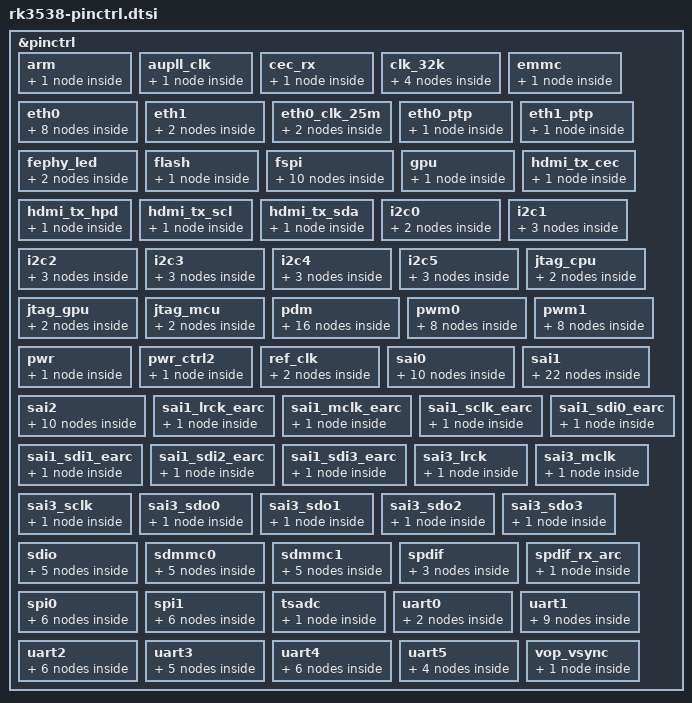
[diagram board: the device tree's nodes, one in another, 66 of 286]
// SPDX-License-Identifier: (GPL-2.0+ OR MIT)
/*
 * Copyright (c) 2025 Rockchip Electronics Co., Ltd.
 */

#include <dt-bindings/pinctrl/rockchip.h>
#include "rv1126b-pinconf.dtsi"

/*
 * This file is auto generated by pin2dts tool, please keep these code
 * by adding changes at end of this file.
 */
&pinctrl {
	arm {
		/omit-if-no-ref/
		arm_pins: arm-pins {
			rockchip,pins =
				/* arm_avs */
				<0 RK_PB5 3 &pcfg_pull_none>;
		};
	};

	aupll_clk {
		/omit-if-no-ref/
		aupll_clk_pins: aupll-clk-pins {
			rockchip,pins =
				/* aupll_clk_in */
				<0 RK_PA1 3 &pcfg_pull_none>;
		};
	};

	cec_rx {
		/omit-if-no-ref/
		cec_rx_pins: cec-rx-pins {
			rockchip,pins =
				/* cec_rx_testout */
				<0 RK_PD1 3 &pcfg_pull_none>;
		};
	};

	clk_32k {
		/omit-if-no-ref/
		clk_32km0_pins: clk-32km0-pins {
			rockchip,pins =
				/* clk_32k_out_m0 */
				<3 RK_PC2 3 &pcfg_pull_none>;
		};

		/omit-if-no-ref/
		clk_32km1_pins: clk-32km1-pins {
			rockchip,pins =
				/* clk_32k_out_m1 */
				<5 RK_PC2 6 &pcfg_pull_none>;
		};

		/omit-if-no-ref/
		clk_32km2_pins: clk-32km2-pins {
			rockchip,pins =
				/* clk_32k_out_m2 */
				<0 RK_PD4 1 &pcfg_pull_none>;
		};

		/omit-if-no-ref/
		clk_32k_in_pins: clk-32k-in-pins {
			rockchip,pins =
				/* clk_32k_in */
				<0 RK_PD4 3 &pcfg_pull_none>;
		};
	};

	emmc {
		/omit-if-no-ref/
		emmc_pins: emmc-pins {
			rockchip,pins =
				/* emmc_clk */
				<1 RK_PB1 1 &pcfg_pull_none>,
				/* emmc_cmd */
				<1 RK_PB0 1 &pcfg_pull_none>,
				/* emmc_d0 */
				<1 RK_PA0 1 &pcfg_pull_none>,
				/* emmc_d1 */
				<1 RK_PA1 1 &pcfg_pull_none>,
				/* emmc_d2 */
				<1 RK_PA2 1 &pcfg_pull_none>,
				/* emmc_d3 */
				<1 RK_PA3 1 &pcfg_pull_none>,
				/* emmc_d4 */
				<1 RK_PA4 1 &pcfg_pull_none>,
				/* emmc_d5 */
				<1 RK_PA5 1 &pcfg_pull_none>,
				/* emmc_d6 */
				<1 RK_PA6 1 &pcfg_pull_none>,
				/* emmc_d7 */
				<1 RK_PA7 1 &pcfg_pull_none>,
				/* emmc_rstn */
				<1 RK_PB3 1 &pcfg_pull_none>,
				/* emmc_strb */
				<1 RK_PB2 1 &pcfg_pull_none>;
		};
	};

	eth0 {
		/omit-if-no-ref/
		eth0_miim_pins: eth0-miim-pins {
			rockchip,pins =
				/* eth0_mdc */
				<5 RK_PB5 1 &pcfg_pull_none>,
				/* eth0_mdio */
				<5 RK_PB6 1 &pcfg_pull_none>;
		};

		/omit-if-no-ref/
		eth0_mclk_pins: eth0-mclk-pins {
			rockchip,pins =
				/* eth0_mclk */
				<5 RK_PB3 1 &pcfg_pull_none>;
		};

		/omit-if-no-ref/
		eth0_rx_bus2_pins: eth0-rx-bus2-pins {
			rockchip,pins =
				/* eth0_rxctl */
				<5 RK_PC1 1 &pcfg_pull_none>,
				/* eth0_rxd0 */
				<5 RK_PB2 1 &pcfg_pull_none>,
				/* eth0_rxd1 */
				<5 RK_PB1 1 &pcfg_pull_none>;
		};

		/omit-if-no-ref/
		eth0_tx_bus2_pins: eth0-tx-bus2-pins {
			rockchip,pins =
				/* eth0_txctl */
				<5 RK_PB7 1 &pcfg_pull_none>,
				/* eth0_txd0 */
				<5 RK_PB0 1 &pcfg_pull_none>,
				/* eth0_txd1 */
				<5 RK_PA7 1 &pcfg_pull_none>;
		};

		/omit-if-no-ref/
		eth0_rgmii_clk_pins: eth0-rgmii-clk-pins {
			rockchip,pins =
				/* eth0_rxclk */
				<5 RK_PA4 1 &pcfg_pull_none>,
				/* eth0_txclk */
				<5 RK_PA5 1 &pcfg_pull_none>;
		};

		/omit-if-no-ref/
		eth0_rgmii_bus_pins: eth0-rgmii-bus-pins {
			rockchip,pins =
				/* eth0_rxd2 */
				<5 RK_PA1 1 &pcfg_pull_none>,
				/* eth0_rxd3 */
				<5 RK_PA0 1 &pcfg_pull_none>,
				/* eth0_txd2 */
				<5 RK_PA3 1 &pcfg_pull_none>,
				/* eth0_txd3 */
				<5 RK_PA2 1 &pcfg_pull_none>;
		};

		/omit-if-no-ref/
		eth0_ppsclk_pins: eth0-ppsclk-pins {
			rockchip,pins =
				/* eth0_ppsclk */
				<5 RK_PC0 3 &pcfg_pull_none>;
		};

		/omit-if-no-ref/
		eth0_ppstrig_pins: eth0-ppstrig-pins {
			rockchip,pins =
				/* eth0_ppstrig */
				<5 RK_PA6 1 &pcfg_pull_none>;
		};
	};

	eth1 {
		/omit-if-no-ref/
		eth1_ppsclk_pins: eth1-ppsclk-pins {
			rockchip,pins =
				/* eth1_ppsclk */
				<6 RK_PA4 2 &pcfg_pull_none>;
		};

		/omit-if-no-ref/
		eth1_ppstrig_pins: eth1-ppstrig-pins {
			rockchip,pins =
				/* eth1_ppstrig */
				<6 RK_PA2 2 &pcfg_pull_none>;
		};
	};

	eth0_clk_25m {
		/omit-if-no-ref/
		eth0m0_clk_25m_out_pins: eth0m0-clk-25m-out-pins {
			rockchip,pins =
				/* eth0m0_clk_25m_out */
				<0 RK_PD5 1 &pcfg_pull_none>;
		};

		/omit-if-no-ref/
		eth0m1_clk_25m_out_pins: eth0m1-clk-25m-out-pins {
			rockchip,pins =
				/* eth0m1_clk_25m_out */
				<0 RK_PB4 1 &pcfg_pull_none>;
		};
	};

	eth0_ptp {
		/omit-if-no-ref/
		eth0_ptp_refclk_pins: eth0-ptp-refclk-pins {
			rockchip,pins =
				/* eth0_ptp_refclk */
				<5 RK_PC3 2 &pcfg_pull_none>;
		};
	};

	eth1_ptp {
		/omit-if-no-ref/
		eth1_ptp_refclk_pins: eth1-ptp-refclk-pins {
			rockchip,pins =
				/* eth1_ptp_refclk */
				<6 RK_PB0 3 &pcfg_pull_none>;
		};
	};

	fephy_led {
		/omit-if-no-ref/
		fephy_ledm0_pins: fephy-ledm0-pins {
			rockchip,pins =
				/* fephy_led_link_m0 */
				<6 RK_PB2 2 &pcfg_pull_none>,
				/* fephy_led_spd_m0 */
				<6 RK_PB1 1 &pcfg_pull_none>;
		};

		/omit-if-no-ref/
		fephy_ledm1_pins: fephy-ledm1-pins {
			rockchip,pins =
				/* fephy_led_link_m1 */
				<2 RK_PA4 4 &pcfg_pull_none>,
				/* fephy_led_spd_m1 */
				<2 RK_PA5 3 &pcfg_pull_none>;
		};
	};

	flash {
		/omit-if-no-ref/
		flash_pins: flash-pins {
			rockchip,pins =
				/* flash_ale */
				<1 RK_PB4 2 &pcfg_pull_none>,
				/* flash_cle */
				<1 RK_PB2 3 &pcfg_pull_none>,
				/* flash_csn0 */
				<1 RK_PB7 2 &pcfg_pull_none>,
				/* flash_csn1 */
				<1 RK_PC0 2 &pcfg_pull_none>,
				/* flash_d0 */
				<1 RK_PA6 3 &pcfg_pull_none>,
				/* flash_d1 */
				<1 RK_PA7 3 &pcfg_pull_none>,
				/* flash_d2 */
				<1 RK_PA2 2 &pcfg_pull_none>,
				/* flash_d3 */
				<1 RK_PA1 2 &pcfg_pull_none>,
				/* flash_d4 */
				<1 RK_PA0 2 &pcfg_pull_none>,
				/* flash_d5 */
				<1 RK_PA4 3 &pcfg_pull_none>,
				/* flash_d6 */
				<1 RK_PA3 2 &pcfg_pull_none>,
				/* flash_d7 */
				<1 RK_PA5 3 &pcfg_pull_none>,
				/* flash_rdn */
				<1 RK_PB6 2 &pcfg_pull_none>,
				/* flash_rdy */
				<1 RK_PB5 2 &pcfg_pull_none>,
				/* flash_wpn */
				<1 RK_PB3 3 &pcfg_pull_none>,
				/* flash_wrn */
				<1 RK_PB0 3 &pcfg_pull_none>;
		};
	};

	fspi {
		/omit-if-no-ref/
		fspi_bus4_pins: fspi-bus4-pins {
			rockchip,pins =
				/* fspi_d0 */
				<1 RK_PB3 2 &pcfg_pull_none>,
				/* fspi_d1 */
				<1 RK_PB6 1 &pcfg_pull_none>,
				/* fspi_d2 */
				<1 RK_PB5 1 &pcfg_pull_none>,
				/* fspi_d3 */
				<1 RK_PC0 1 &pcfg_pull_none>;
		};

		/omit-if-no-ref/
		fspi_clk_pins: fspi-clk-pins {
			rockchip,pins =
				/* fspi_clk */
				<1 RK_PB4 1 &pcfg_pull_none>;
		};
		/omit-if-no-ref/
		fspi_csn0_pins: fspi-csn0-pins {
			rockchip,pins =
				/* fspi_csn0 */
				<1 RK_PB7 1 &pcfg_pull_none>;
		};
		/omit-if-no-ref/
		fspi_csn1_pins: fspi-csn1-pins {
			rockchip,pins =
				/* fspi_csn1 */
				<1 RK_PB0 2 &pcfg_pull_none>;
		};
		/omit-if-no-ref/
		fspi_d4_pins: fspi-d4-pins {
			rockchip,pins =
				/* fspi_d4 */
				<1 RK_PA5 2 &pcfg_pull_none>;
		};
		/omit-if-no-ref/
		fspi_d5_pins: fspi-d5-pins {
			rockchip,pins =
				/* fspi_d5 */
				<1 RK_PA4 2 &pcfg_pull_none>;
		};
		/omit-if-no-ref/
		fspi_d6_pins: fspi-d6-pins {
			rockchip,pins =
				/* fspi_d6 */
				<1 RK_PA7 2 &pcfg_pull_none>;
		};
		/omit-if-no-ref/
		fspi_d7_pins: fspi-d7-pins {
			rockchip,pins =
				/* fspi_d7 */
				<1 RK_PA6 2 &pcfg_pull_none>;
		};
		/omit-if-no-ref/
		fspi_dqs_pins: fspi-dqs-pins {
			rockchip,pins =
				/* fspi_dqs */
				<1 RK_PB1 2 &pcfg_pull_none>;
		};
		/omit-if-no-ref/
		fspi_rstn_pins: fspi-rstn-pins {
			rockchip,pins =
				/* fspi_rstn */
				<1 RK_PB2 2 &pcfg_pull_none>;
		};
	};

	gpu {
		/omit-if-no-ref/
		gpu_pins: gpu-pins {
			rockchip,pins =
				/* gpu_avs */
				<0 RK_PB4 3 &pcfg_pull_none>;
		};
	};

	hdmi_tx_cec {
		/omit-if-no-ref/
		hdmi_tx_cec_pins: hdmi-tx-cec-pins {
			rockchip,pins =
				/* hdmi_tx_cec_3v3 */
				<0 RK_PA7 1 &pcfg_pull_up>;
		};
	};

	hdmi_tx_hpd {
		/omit-if-no-ref/
		hdmi_tx_hpd_pins: hdmi-tx-hpd-pins {
			rockchip,pins =
				/* hdmi_tx_hpd_5v */
				<0 RK_PA6 1 &pcfg_pull_none>;
		};
	};

	hdmi_tx_scl {
		/omit-if-no-ref/
		hdmi_tx_scl_pins: hdmi-tx-scl-pins {
			rockchip,pins =
				/* hdmi_tx_scl_5v */
				<0 RK_PB0 1 &pcfg_pull_none_smt>;
		};
	};

	hdmi_tx_sda {
		/omit-if-no-ref/
		hdmi_tx_sda_pins: hdmi-tx-sda-pins {
			rockchip,pins =
				/* hdmi_tx_sda_5v */
				<0 RK_PB1 1 &pcfg_pull_none_smt>;
		};
	};

	i2c0 {
		/omit-if-no-ref/
		i2c0m0_pins: i2c0m0-pins {
			rockchip,pins =
				/* i2c0_scl_m0 */
				<0 RK_PB5 1 &pcfg_pull_none_smt>,
				/* i2c0_sda_m0 */
				<0 RK_PB6 1 &pcfg_pull_none_smt>;
		};

		/omit-if-no-ref/
		i2c0m1_pins: i2c0m1-pins {
			rockchip,pins =
				/* i2c0_scl_m1 */
				<0 RK_PD2 1 &pcfg_pull_none_smt>,
				/* i2c0_sda_m1 */
				<0 RK_PD3 1 &pcfg_pull_none_smt>;
		};
	};

	i2c1 {
		/omit-if-no-ref/
		i2c1m0_pins: i2c1m0-pins {
			rockchip,pins =
				/* i2c1_scl_m0 */
				<6 RK_PB2 3 &pcfg_pull_none_smt>,
				/* i2c1_sda_m0 */
				<6 RK_PB1 2 &pcfg_pull_none_smt>;
		};

		/omit-if-no-ref/
		i2c1m1_pins: i2c1m1-pins {
			rockchip,pins =
				/* i2c1_scl_m1 */
				<5 RK_PB7 5 &pcfg_pull_none_smt>,
				/* i2c1_sda_m1 */
				<5 RK_PB6 4 &pcfg_pull_none_smt>;
		};

		/omit-if-no-ref/
		i2c1m2_pins: i2c1m2-pins {
			rockchip,pins =
				/* i2c1_scl_m2 */
				<4 RK_PA5 2 &pcfg_pull_none_smt>,
				/* i2c1_sda_m2 */
				<4 RK_PA6 2 &pcfg_pull_none_smt>;
		};
	};

	i2c2 {
		/omit-if-no-ref/
		i2c2m0_pins: i2c2m0-pins {
			rockchip,pins =
				/* i2c2_scl_m0 */
				<3 RK_PB3 4 &pcfg_pull_none_smt>,
				/* i2c2_sda_m0 */
				<3 RK_PA6 4 &pcfg_pull_none_smt>;
		};

		/omit-if-no-ref/
		i2c2m1_pins: i2c2m1-pins {
			rockchip,pins =
				/* i2c2_scl_m1 */
				<0 RK_PB0 2 &pcfg_pull_none_smt>,
				/* i2c2_sda_m1 */
				<0 RK_PB1 2 &pcfg_pull_none_smt>;
		};

		/omit-if-no-ref/
		i2c2m2_pins: i2c2m2-pins {
			rockchip,pins =
				/* i2c2_scl_m2 */
				<6 RK_PC2 1 &pcfg_pull_none_smt>,
				/* i2c2_sda_m2 */
				<6 RK_PC3 1 &pcfg_pull_none_smt>;
		};
	};

	i2c3 {
		/omit-if-no-ref/
		i2c3m0_pins: i2c3m0-pins {
			rockchip,pins =
				/* i2c3_scl_m0 */
				<3 RK_PC2 4 &pcfg_pull_none_smt>,
				/* i2c3_sda_m0 */
				<3 RK_PC3 3 &pcfg_pull_none_smt>;
		};

		/omit-if-no-ref/
		i2c3m1_pins: i2c3m1-pins {
			rockchip,pins =
				/* i2c3_scl_m1 */
				<5 RK_PC0 6 &pcfg_pull_none_smt>,
				/* i2c3_sda_m1 */
				<5 RK_PC2 5 &pcfg_pull_none_smt>;
		};

		/omit-if-no-ref/
		i2c3m2_pins: i2c3m2-pins {
			rockchip,pins =
				/* i2c3_scl_m2 */
				<6 RK_PB0 2 &pcfg_pull_none_smt>,
				/* i2c3_sda_m2 */
				<6 RK_PA7 2 &pcfg_pull_none_smt>;
		};
	};

	i2c4 {
		/omit-if-no-ref/
		i2c4m0_pins: i2c4m0-pins {
			rockchip,pins =
				/* i2c4_scl_m0 */
				<3 RK_PC0 1 &pcfg_pull_none_smt>,
				/* i2c4_sda_m0 */
				<3 RK_PC1 1 &pcfg_pull_none_smt>;
		};

		/omit-if-no-ref/
		i2c4m1_pins: i2c4m1-pins {
			rockchip,pins =
				/* i2c4_scl_m1 */
				<2 RK_PA1 4 &pcfg_pull_none_smt>,
				/* i2c4_sda_m1 */
				<2 RK_PA0 4 &pcfg_pull_none_smt>;
		};

		/omit-if-no-ref/
		i2c4m2_pins: i2c4m2-pins {
			rockchip,pins =
				/* i2c4_scl_m2 */
				<1 RK_PA4 4 &pcfg_pull_none_smt>,
				/* i2c4_sda_m2 */
				<1 RK_PA5 4 &pcfg_pull_none_smt>;
		};
	};

	i2c5 {
		/omit-if-no-ref/
		i2c5m0_pins: i2c5m0-pins {
			rockchip,pins =
				/* i2c5_scl_m0 */
				<5 RK_PA4 4 &pcfg_pull_none_smt>,
				/* i2c5_sda_m0 */
				<5 RK_PA5 3 &pcfg_pull_none_smt>;
		};

		/omit-if-no-ref/
		i2c5m1_pins: i2c5m1-pins {
			rockchip,pins =
				/* i2c5_scl_m1 */
				<1 RK_PB1 3 &pcfg_pull_none_smt>,
				/* i2c5_sda_m1 */
				<1 RK_PC0 3 &pcfg_pull_none_smt>;
		};

		/omit-if-no-ref/
		i2c5m2_pins: i2c5m2-pins {
			rockchip,pins =
				/* i2c5_scl_m2 */
				<0 RK_PD0 2 &pcfg_pull_none_smt>,
				/* i2c5_sda_m2 */
				<0 RK_PD1 2 &pcfg_pull_none_smt>;
		};
	};

	jtag_cpu {
		/omit-if-no-ref/
		jtag_cpum0_pins: jtag-cpum0-pins {
			rockchip,pins =
				/* jtag_cpu_tck_m0 */
				<2 RK_PA2 2 &pcfg_pull_none>,
				/* jtag_cpu_tms_m0 */
				<2 RK_PA3 2 &pcfg_pull_none>;
		};

		/omit-if-no-ref/
		jtag_cpum1_pins: jtag-cpum1-pins {
			rockchip,pins =
				/* jtag_cpu_tck_m1 */
				<0 RK_PC0 2 &pcfg_pull_none>,
				/* jtag_cpu_tms_m1 */
				<0 RK_PB7 2 &pcfg_pull_none>;
		};
	};

	jtag_gpu {
		/omit-if-no-ref/
		jtag_gpum0_pins: jtag-gpum0-pins {
			rockchip,pins =
				/* jtag_gpu_tck_m0 */
				<2 RK_PA2 5 &pcfg_pull_none>,
				/* jtag_gpu_tms_m0 */
				<2 RK_PA3 5 &pcfg_pull_none>;
		};

		/omit-if-no-ref/
		jtag_gpum1_pins: jtag-gpum1-pins {
			rockchip,pins =
				/* jtag_gpu_tck_m1 */
				<0 RK_PC0 4 &pcfg_pull_none>,
				/* jtag_gpu_tms_m1 */
				<0 RK_PB7 4 &pcfg_pull_none>;
		};
	};

	jtag_mcu {
		/omit-if-no-ref/
		jtag_mcum0_pins: jtag-mcum0-pins {
			rockchip,pins =
				/* jtag_mcu_tck_m0 */
				<2 RK_PA2 4 &pcfg_pull_none>,
				/* jtag_mcu_tms_m0 */
				<2 RK_PA3 4 &pcfg_pull_none>;
		};

		/omit-if-no-ref/
		jtag_mcum1_pins: jtag-mcum1-pins {
			rockchip,pins =
				/* jtag_mcu_tck_m1 */
				<0 RK_PC0 3 &pcfg_pull_none>,
				/* jtag_mcu_tms_m1 */
				<0 RK_PB7 3 &pcfg_pull_none>;
		};
	};

	pdm {
		/omit-if-no-ref/
		pdmm0_clk0_pins: pdmm0-clk0-pins {
			rockchip,pins =
				/* pdm_clk0_m0 */
				<6 RK_PA5 1 &pcfg_pull_none>;
		};

		/omit-if-no-ref/
		pdmm0_clk1_pins: pdmm0-clk1-pins {
			rockchip,pins =
				/* pdm_clk1_m0 */
				<6 RK_PA7 1 &pcfg_pull_none>;
		};

		/omit-if-no-ref/
		pdmm0_sdi0_pins: pdmm0-sdi0-pins {
			rockchip,pins =
				/* pdm_sdi0_m0 */
				<6 RK_PA1 2 &pcfg_pull_none>;
		};

		/omit-if-no-ref/
		pdmm0_sdi1_pins: pdmm0-sdi1-pins {
			rockchip,pins =
				/* pdm_sdi1_m0 */
				<6 RK_PA4 1 &pcfg_pull_none>;
		};

		/omit-if-no-ref/
		pdmm0_sdi2_pins: pdmm0-sdi2-pins {
			rockchip,pins =
				/* pdm_sdi2_m0 */
				<6 RK_PA6 1 &pcfg_pull_none>;
		};

		/omit-if-no-ref/
		pdmm0_sdi3_pins: pdmm0-sdi3-pins {
			rockchip,pins =
				/* pdm_sdi3_m0 */
				<6 RK_PB0 1 &pcfg_pull_none>;
		};

		/omit-if-no-ref/
		pdmm1_clk0_pins: pdmm1-clk0-pins {
			rockchip,pins =
				/* pdm_clk0_m1 */
				<5 RK_PA6 4 &pcfg_pull_none>;
		};

		/omit-if-no-ref/
		pdmm1_clk1_pins: pdmm1-clk1-pins {
			rockchip,pins =
				/* pdm_clk1_m1 */
				<5 RK_PB7 4 &pcfg_pull_none>;
		};

		/omit-if-no-ref/
		pdmm1_sdi0_pins: pdmm1-sdi0-pins {
			rockchip,pins =
				/* pdm_sdi0_m1 */
				<5 RK_PC0 5 &pcfg_pull_none>;
		};

		/omit-if-no-ref/
		pdmm1_sdi1_pins: pdmm1-sdi1-pins {
			rockchip,pins =
				/* pdm_sdi1_m1 */
				<5 RK_PC3 4 &pcfg_pull_none>;
		};

		/omit-if-no-ref/
		pdmm1_sdi2_pins: pdmm1-sdi2-pins {
			rockchip,pins =
				/* pdm_sdi2_m1 */
				<5 RK_PC1 3 &pcfg_pull_none>;
		};

		/omit-if-no-ref/
		pdmm1_sdi3_pins: pdmm1-sdi3-pins {
			rockchip,pins =
				/* pdm_sdi3_m1 */
				<5 RK_PB4 3 &pcfg_pull_none>;
		};
	};

	pwm0 {
		/omit-if-no-ref/
		pwm0m0_ch0_pins: pwm0m0-ch0-pins {
			rockchip,pins =
				/* pwm0m0_ch0 */
				<0 RK_PA2 2 &pcfg_pull_none>;
		};
		/omit-if-no-ref/
		pwm0m0_ch1_pins: pwm0m0-ch1-pins {
			rockchip,pins =
				/* pwm0m0_ch1 */
				<0 RK_PA5 1 &pcfg_pull_none>;
		};
		/omit-if-no-ref/
		pwm0m0_ch2_pins: pwm0m0-ch2-pins {
			rockchip,pins =
				/* pwm0m0_ch2 */
				<0 RK_PB5 2 &pcfg_pull_none>;
		};
		/omit-if-no-ref/
		pwm0m0_ch3_pins: pwm0m0-ch3-pins {
			rockchip,pins =
				/* pwm0m0_ch3 */
				<0 RK_PB6 2 &pcfg_pull_none>;
		};

		/omit-if-no-ref/
		pwm0m1_ch0_pins: pwm0m1-ch0-pins {
			rockchip,pins =
				/* pwm0m1_ch0 */
				<0 RK_PA3 2 &pcfg_pull_none>;
		};
		/omit-if-no-ref/
		pwm0m1_ch1_pins: pwm0m1-ch1-pins {
			rockchip,pins =
				/* pwm0m1_ch1 */
				<0 RK_PB2 1 &pcfg_pull_none>;
		};
		/omit-if-no-ref/
		pwm0m1_ch2_pins: pwm0m1-ch2-pins {
			rockchip,pins =
				/* pwm0m1_ch2 */
				<0 RK_PB3 1 &pcfg_pull_none>;
		};
		/omit-if-no-ref/
		pwm0m1_ch3_pins: pwm0m1-ch3-pins {
			rockchip,pins =
				/* pwm0m1_ch3 */
				<0 RK_PB4 2 &pcfg_pull_none>;
		};
	};

	pwm1 {
		/omit-if-no-ref/
		pwm1m0_ch0_pins: pwm1m0-ch0-pins {
			rockchip,pins =
				/* pwm1m0_ch0 */
				<6 RK_PC1 3 &pcfg_pull_none>;
		};
		/omit-if-no-ref/
		pwm1m0_ch1_pins: pwm1m0-ch1-pins {
			rockchip,pins =
				/* pwm1m0_ch1 */
				<6 RK_PC5 3 &pcfg_pull_none>;
		};
		/omit-if-no-ref/
		pwm1m0_ch2_pins: pwm1m0-ch2-pins {
			rockchip,pins =
				/* pwm1m0_ch2 */
				<6 RK_PC6 2 &pcfg_pull_none>;
		};
		/omit-if-no-ref/
		pwm1m0_ch3_pins: pwm1m0-ch3-pins {
			rockchip,pins =
				/* pwm1m0_ch3 */
				<6 RK_PC4 3 &pcfg_pull_none>;
		};

		/omit-if-no-ref/
		pwm1m1_ch0_pins: pwm1m1-ch0-pins {
			rockchip,pins =
				/* pwm1m1_ch0 */
				<6 RK_PA6 2 &pcfg_pull_none>;
		};
		/omit-if-no-ref/
		pwm1m1_ch1_pins: pwm1m1-ch1-pins {
			rockchip,pins =
				/* pwm1m1_ch1 */
				<6 RK_PA5 2 &pcfg_pull_none>;
		};
		/omit-if-no-ref/
		pwm1m1_ch2_pins: pwm1m1-ch2-pins {
			rockchip,pins =
				/* pwm1m1_ch2 */
				<6 RK_PA4 3 &pcfg_pull_none>;
		};
		/omit-if-no-ref/
		pwm1m1_ch3_pins: pwm1m1-ch3-pins {
			rockchip,pins =
				/* pwm1m1_ch3 */
				<6 RK_PB0 4 &pcfg_pull_none>;
		};
	};

	pwr {
		/omit-if-no-ref/
		pwr_pins: pwr-pins {
			rockchip,pins =
				/* pwr_ctrl0 */
				<0 RK_PA2 1 &pcfg_pull_none>,
				/* pwr_ctrl1 */
				<0 RK_PA3 1 &pcfg_pull_none>;
		};
	};

	pwr_ctrl2 {
		/omit-if-no-ref/
		pwr_ctrl2_pins: pwr-ctrl2-pins {
			rockchip,pins =
				/* pwr_ctrl2_5v */
				<0 RK_PA4 1 &pcfg_pull_none>;
		};
	};

	ref_clk {
		/omit-if-no-ref/
		ref_clkm0_pins: ref-clkm0-pins {
			rockchip,pins =
				/* ref_clk_out_m0 */
				<0 RK_PA1 1 &pcfg_pull_none>;
		};

		/omit-if-no-ref/
		ref_clkm1_pins: ref-clkm1-pins {
			rockchip,pins =
				/* ref_clk_out_m1 */
				<5 RK_PC2 2 &pcfg_pull_none>;
		};
	};

	sai0 {
		/omit-if-no-ref/
		sai0m0_lrck_pins: sai0m0-lrck-pins {
			rockchip,pins =
				/* sai0_lrck_m0 */
				<3 RK_PB5 1 &pcfg_pull_none>;
		};

		/omit-if-no-ref/
		sai0m0_mclk_pins: sai0m0-mclk-pins {
			rockchip,pins =
				/* sai0_mclk_m0 */
				<3 RK_PB3 1 &pcfg_pull_none>;
		};

		/omit-if-no-ref/
		sai0m0_sclk_pins: sai0m0-sclk-pins {
			rockchip,pins =
				/* sai0_sclk_m0 */
				<3 RK_PB4 1 &pcfg_pull_none>;
		};

		/omit-if-no-ref/
		sai0m0_sdi_pins: sai0m0-sdi-pins {
			rockchip,pins =
				/* sai0m0_sdi */
				<3 RK_PB6 1 &pcfg_pull_none>;
		};
		/omit-if-no-ref/
		sai0m0_sdo_pins: sai0m0-sdo-pins {
			rockchip,pins =
				/* sai0m0_sdo */
				<3 RK_PB7 1 &pcfg_pull_none>;
		};

		/omit-if-no-ref/
		sai0m1_lrck_pins: sai0m1-lrck-pins {
			rockchip,pins =
				/* sai0_lrck_m1 */
				<5 RK_PC1 2 &pcfg_pull_none>;
		};

		/omit-if-no-ref/
		sai0m1_mclk_pins: sai0m1-mclk-pins {
			rockchip,pins =
				/* sai0_mclk_m1 */
				<5 RK_PC3 3 &pcfg_pull_none>;
		};

		/omit-if-no-ref/
		sai0m1_sclk_pins: sai0m1-sclk-pins {
			rockchip,pins =
				/* sai0_sclk_m1 */
				<5 RK_PC0 2 &pcfg_pull_none>;
		};

		/omit-if-no-ref/
		sai0m1_sdi_pins: sai0m1-sdi-pins {
			rockchip,pins =
				/* sai0m1_sdi */
				<5 RK_PB6 2 &pcfg_pull_none>;
		};
		/omit-if-no-ref/
		sai0m1_sdo_pins: sai0m1-sdo-pins {
			rockchip,pins =
				/* sai0m1_sdo */
				<5 RK_PB7 2 &pcfg_pull_none>;
		};
	};

	sai1 {
		/omit-if-no-ref/
		sai1m0_lrck_pins: sai1m0-lrck-pins {
			rockchip,pins =
				/* sai1_lrck_m0 */
				<6 RK_PC0 1 &pcfg_pull_none>;
		};

		/omit-if-no-ref/
		sai1m0_mclk_pins: sai1m0-mclk-pins {
			rockchip,pins =
				/* sai1_mclk_m0 */
				<6 RK_PC1 2 &pcfg_pull_none>;
		};

		/omit-if-no-ref/
		sai1m0_sclk_pins: sai1m0-sclk-pins {
			rockchip,pins =
				/* sai1_sclk_m0 */
				<6 RK_PB7 1 &pcfg_pull_none>;
		};

		/omit-if-no-ref/
		sai1m0_sdi0_pins: sai1m0-sdi0-pins {
			rockchip,pins =
				/* sai1_sdi0_m0 */
				<6 RK_PB6 1 &pcfg_pull_none>;
		};

		/omit-if-no-ref/
		sai1m0_sdi1_pins: sai1m0-sdi1-pins {
			rockchip,pins =
				/* sai1_sdi1_m0 */
				<6 RK_PB4 1 &pcfg_pull_none>;
		};

		/omit-if-no-ref/
		sai1m0_sdi2_pins: sai1m0-sdi2-pins {
			rockchip,pins =
				/* sai1_sdi2_m0 */
				<6 RK_PB2 1 &pcfg_pull_none>;
		};

		/omit-if-no-ref/
		sai1m0_sdi3_pins: sai1m0-sdi3-pins {
			rockchip,pins =
				/* sai1_sdi3_m0 */
				<6 RK_PC5 2 &pcfg_pull_none>;
		};

		/omit-if-no-ref/
		sai1m0_sdo0_pins: sai1m0-sdo0-pins {
			rockchip,pins =
				/* sai1_sdo0_m0 */
				<6 RK_PB3 1 &pcfg_pull_none>;
		};

		/omit-if-no-ref/
		sai1m0_sdo1_pins: sai1m0-sdo1-pins {
			rockchip,pins =
				/* sai1_sdo1_m0 */
				<6 RK_PB5 1 &pcfg_pull_none>;
		};

		/omit-if-no-ref/
		sai1m0_sdo2_pins: sai1m0-sdo2-pins {
			rockchip,pins =
				/* sai1_sdo2_m0 */
				<6 RK_PC4 2 &pcfg_pull_none>;
		};

		/omit-if-no-ref/
		sai1m0_sdo3_pins: sai1m0-sdo3-pins {
			rockchip,pins =
				/* sai1_sdo3_m0 */
				<6 RK_PC6 1 &pcfg_pull_none>;
		};

		/omit-if-no-ref/
		sai1m1_lrck_pins: sai1m1-lrck-pins {
			rockchip,pins =
				/* sai1_lrck_m1 */
				<5 RK_PB0 2 &pcfg_pull_none>;
		};

		/omit-if-no-ref/
		sai1m1_mclk_pins: sai1m1-mclk-pins {
			rockchip,pins =
				/* sai1_mclk_m1 */
				<5 RK_PA6 3 &pcfg_pull_none>;
		};

		/omit-if-no-ref/
		sai1m1_sclk_pins: sai1m1-sclk-pins {
			rockchip,pins =
				/* sai1_sclk_m1 */
				<5 RK_PA7 2 &pcfg_pull_none>;
		};

		/omit-if-no-ref/
		sai1m1_sdi0_pins: sai1m1-sdi0-pins {
			rockchip,pins =
				/* sai1_sdi0_m1 */
				<5 RK_PB2 2 &pcfg_pull_none>;
		};

		/omit-if-no-ref/
		sai1m1_sdi1_pins: sai1m1-sdi1-pins {
			rockchip,pins =
				/* sai1_sdi1_m1 */
				<5 RK_PB3 2 &pcfg_pull_none>;
		};

		/omit-if-no-ref/
		sai1m1_sdi2_pins: sai1m1-sdi2-pins {
			rockchip,pins =
				/* sai1_sdi2_m1 */
				<5 RK_PB4 1 &pcfg_pull_none>;
		};

		/omit-if-no-ref/
		sai1m1_sdi3_pins: sai1m1-sdi3-pins {
			rockchip,pins =
				/* sai1_sdi3_m1 */
				<5 RK_PB5 2 &pcfg_pull_none>;
		};

		/omit-if-no-ref/
		sai1m1_sdo0_pins: sai1m1-sdo0-pins {
			rockchip,pins =
				/* sai1_sdo0_m1 */
				<5 RK_PB1 2 &pcfg_pull_none>;
		};

		/omit-if-no-ref/
		sai1m1_sdo1_pins: sai1m1-sdo1-pins {
			rockchip,pins =
				/* sai1_sdo1_m1 */
				<5 RK_PB5 3 &pcfg_pull_none>;
		};

		/omit-if-no-ref/
		sai1m1_sdo2_pins: sai1m1-sdo2-pins {
			rockchip,pins =
				/* sai1_sdo2_m1 */
				<5 RK_PB4 2 &pcfg_pull_none>;
		};

		/omit-if-no-ref/
		sai1m1_sdo3_pins: sai1m1-sdo3-pins {
			rockchip,pins =
				/* sai1_sdo3_m1 */
				<5 RK_PB3 3 &pcfg_pull_none>;
		};
	};

	sai2 {
		/omit-if-no-ref/
		sai2m0_lrck_pins: sai2m0-lrck-pins {
			rockchip,pins =
				/* sai2_lrck_m0 */
				<4 RK_PA2 3 &pcfg_pull_none>;
		};

		/omit-if-no-ref/
		sai2m0_mclk_pins: sai2m0-mclk-pins {
			rockchip,pins =
				/* sai2_mclk_m0 */
				<4 RK_PA0 3 &pcfg_pull_none>;
		};

		/omit-if-no-ref/
		sai2m0_sclk_pins: sai2m0-sclk-pins {
			rockchip,pins =
				/* sai2_sclk_m0 */
				<4 RK_PA1 3 &pcfg_pull_none>;
		};

		/omit-if-no-ref/
		sai2m0_sdi_pins: sai2m0-sdi-pins {
			rockchip,pins =
				/* sai2m0_sdi */
				<4 RK_PA3 3 &pcfg_pull_none>;
		};
		/omit-if-no-ref/
		sai2m0_sdo_pins: sai2m0-sdo-pins {
			rockchip,pins =
				/* sai2m0_sdo */
				<4 RK_PA4 3 &pcfg_pull_none>;
		};

		/omit-if-no-ref/
		sai2m1_lrck_pins: sai2m1-lrck-pins {
			rockchip,pins =
				/* sai2_lrck_m1 */
				<5 RK_PA2 3 &pcfg_pull_none>;
		};

		/omit-if-no-ref/
		sai2m1_mclk_pins: sai2m1-mclk-pins {
			rockchip,pins =
				/* sai2_mclk_m1 */
				<5 RK_PA0 2 &pcfg_pull_none>;
		};

		/omit-if-no-ref/
		sai2m1_sclk_pins: sai2m1-sclk-pins {
			rockchip,pins =
				/* sai2_sclk_m1 */
				<5 RK_PA1 3 &pcfg_pull_none>;
		};

		/omit-if-no-ref/
		sai2m1_sdi_pins: sai2m1-sdi-pins {
			rockchip,pins =
				/* sai2m1_sdi */
				<5 RK_PA3 3 &pcfg_pull_none>;
		};
		/omit-if-no-ref/
		sai2m1_sdo_pins: sai2m1-sdo-pins {
			rockchip,pins =
				/* sai2m1_sdo */
				<5 RK_PA4 3 &pcfg_pull_none>;
		};
	};

	sai1_lrck_earc {
		/omit-if-no-ref/
		sai1_lrck_earc_lrck_pins: sai1-lrck-earc-lrck-pins {
			rockchip,pins =
				/* sai1_lrck_earc_testout */
				<4 RK_PA2 4 &pcfg_pull_none>;
		};
	};

	sai1_mclk_earc {
		/omit-if-no-ref/
		sai1_mclk_earc_mclk_pins: sai1-mclk-earc-mclk-pins {
			rockchip,pins =
				/* sai1_mclk_earc_testout */
				<4 RK_PA0 4 &pcfg_pull_none>;
		};
	};

	sai1_sclk_earc {
		/omit-if-no-ref/
		sai1_sclk_earc_sclk_pins: sai1-sclk-earc-sclk-pins {
			rockchip,pins =
				/* sai1_sclk_earc_testout */
				<4 RK_PA1 4 &pcfg_pull_none>;
		};
	};

	sai1_sdi0_earc {
		/omit-if-no-ref/
		sai1_sdi0_earc_sdi0_pins: sai1-sdi0-earc-sdi0-pins {
			rockchip,pins =
				/* sai1_sdi0_earc_testout */
				<4 RK_PA3 4 &pcfg_pull_none>;
		};
	};

	sai1_sdi1_earc {
		/omit-if-no-ref/
		sai1_sdi1_earc_sdi1_pins: sai1-sdi1-earc-sdi1-pins {
			rockchip,pins =
				/* sai1_sdi1_earc_testout */
				<4 RK_PA4 4 &pcfg_pull_none>;
		};
	};

	sai1_sdi2_earc {
		/omit-if-no-ref/
		sai1_sdi2_earc_sdi2_pins: sai1-sdi2-earc-sdi2-pins {
			rockchip,pins =
				/* sai1_sdi2_earc_testout */
				<4 RK_PA5 3 &pcfg_pull_none>;
		};
	};

	sai1_sdi3_earc {
		/omit-if-no-ref/
		sai1_sdi3_earc_sdi3_pins: sai1-sdi3-earc-sdi3-pins {
			rockchip,pins =
				/* sai1_sdi3_earc_testout */
				<4 RK_PA6 3 &pcfg_pull_none>;
		};
	};

	sai3_lrck {
		/omit-if-no-ref/
		sai3_lrck_lrck_pins: sai3-lrck-lrck-pins {
			rockchip,pins =
				/* sai3_lrck_testout */
				<3 RK_PA5 2 &pcfg_pull_none>;
		};
	};

	sai3_mclk {
		/omit-if-no-ref/
		sai3_mclk_mclk_pins: sai3-mclk-mclk-pins {
			rockchip,pins =
				/* sai3_mclk_testout */
				<3 RK_PA6 2 &pcfg_pull_none>;
		};
	};

	sai3_sclk {
		/omit-if-no-ref/
		sai3_sclk_sclk_pins: sai3-sclk-sclk-pins {
			rockchip,pins =
				/* sai3_sclk_testout */
				<3 RK_PA4 2 &pcfg_pull_none>;
		};
	};

	sai3_sdo0 {
		/omit-if-no-ref/
		sai3_sdo0_sdo0_pins: sai3-sdo0-sdo0-pins {
			rockchip,pins =
				/* sai3_sdo0_testout */
				<3 RK_PA0 2 &pcfg_pull_none>;
		};
	};

	sai3_sdo1 {
		/omit-if-no-ref/
		sai3_sdo1_sdo1_pins: sai3-sdo1-sdo1-pins {
			rockchip,pins =
				/* sai3_sdo1_testout */
				<3 RK_PA1 2 &pcfg_pull_none>;
		};
	};

	sai3_sdo2 {
		/omit-if-no-ref/
		sai3_sdo2_sdo2_pins: sai3-sdo2-sdo2-pins {
			rockchip,pins =
				/* sai3_sdo2_testout */
				<3 RK_PA2 2 &pcfg_pull_none>;
		};
	};

	sai3_sdo3 {
		/omit-if-no-ref/
		sai3_sdo3_sdo3_pins: sai3-sdo3-sdo3-pins {
			rockchip,pins =
				/* sai3_sdo3_testout */
				<3 RK_PA3 2 &pcfg_pull_none>;
		};
	};

	sdio {
		/omit-if-no-ref/
		sdio_bus4_pins: sdio-bus4-pins {
			rockchip,pins =
				/* sdio_d0 */
				<3 RK_PA0 1 &pcfg_pull_up_drv_level_1_75>,
				/* sdio_d1 */
				<3 RK_PA1 1 &pcfg_pull_up_drv_level_1_75>,
				/* sdio_d2 */
				<3 RK_PA2 1 &pcfg_pull_up_drv_level_1_75>,
				/* sdio_d3 */
				<3 RK_PA3 1 &pcfg_pull_up_drv_level_1_75>;
		};

		/omit-if-no-ref/
		sdio_clk_pins: sdio-clk-pins {
			rockchip,pins =
				/* sdio_clk */
				<3 RK_PA5 1 &pcfg_pull_up_drv_level_1_75>;
		};

		/omit-if-no-ref/
		sdio_cmd_pins: sdio-cmd-pins {
			rockchip,pins =
				/* sdio_cmd */
				<3 RK_PA4 1 &pcfg_pull_up_drv_level_1_75>;
		};

		/omit-if-no-ref/
		sdio_detn_pins: sdio-detn-pins {
			rockchip,pins =
				/* sdio_detn */
				<3 RK_PA6 1 &pcfg_pull_none>;
		};
		/omit-if-no-ref/
		sdio_pwren_pins: sdio-pwren-pins {
			rockchip,pins =
				/* sdio_pwren */
				<3 RK_PC3 1 &pcfg_pull_none>;
		};
	};

	sdmmc0 {
		/omit-if-no-ref/
		sdmmc0_bus4_pins: sdmmc0-bus4-pins {
			rockchip,pins =
				/* sdmmc0_d0 */
				<2 RK_PA0 1 &pcfg_pull_up_drv_level_2_75>,
				/* sdmmc0_d1 */
				<2 RK_PA1 1 &pcfg_pull_up_drv_level_2_75>,
				/* sdmmc0_d2 */
				<2 RK_PA2 1 &pcfg_pull_up_drv_level_2_75>,
				/* sdmmc0_d3 */
				<2 RK_PA3 1 &pcfg_pull_up_drv_level_2_75>;
		};

		/omit-if-no-ref/
		sdmmc0_cmd_pins: sdmmc0-cmd-pins {
			rockchip,pins =
				/* sdmmc0_cmd */
				<2 RK_PA4 1 &pcfg_pull_up_drv_level_2_75>;
		};

		/omit-if-no-ref/
		sdmmc0_clk_pins: sdmmc0-clk-pins {
			rockchip,pins =
				/* sdmmc0_clk */
				<2 RK_PA5 1 &pcfg_pull_up_drv_level_2_75>;
		};

		/omit-if-no-ref/
		sdmmc0_detn_pins: sdmmc0-detn-pins {
			rockchip,pins =
				/* sdmmc0_detn */
				<2 RK_PA6 1 &pcfg_pull_up>;
		};

		/omit-if-no-ref/
		sdmmc0_pwren_pins: sdmmc0-pwren-pins {
			rockchip,pins =
				/* sdmmc0_pwren */
				<6 RK_PA1 1 &pcfg_pull_none>;
		};
	};

	sdmmc1 {
		/omit-if-no-ref/
		sdmmc1_bus4_pins: sdmmc1-bus4-pins {
			rockchip,pins =
				/* sdmmc1_d0 */
				<4 RK_PA0 1 &pcfg_pull_up>,
				/* sdmmc1_d1 */
				<4 RK_PA1 1 &pcfg_pull_up>,
				/* sdmmc1_d2 */
				<4 RK_PA2 1 &pcfg_pull_up>,
				/* sdmmc1_d3 */
				<4 RK_PA3 1 &pcfg_pull_up>;
		};

		/omit-if-no-ref/
		sdmmc1_cmd_pins: sdmmc1-cmd-pins {
			rockchip,pins =
				/* sdmmc1_cmd */
				<4 RK_PA4 1 &pcfg_pull_up>;
		};

		/omit-if-no-ref/
		sdmmc1_clk_pins: sdmmc1-clk-pins {
			rockchip,pins =
				/* sdmmc1_clk */
				<4 RK_PA5 1 &pcfg_pull_none>;
		};

		/omit-if-no-ref/
		sdmmc1_detn_pins: sdmmc1-detn-pins {
			rockchip,pins =
				/* sdmmc1_detn */
				<4 RK_PA6 1 &pcfg_pull_up>;
		};

		/omit-if-no-ref/
		sdmmc1_pwren_pins: sdmmc1-pwren-pins {
			rockchip,pins =
				/* sdmmc1_pwren */
				<5 RK_PC3 6 &pcfg_pull_none>;
		};
	};

	spdif {
		/omit-if-no-ref/
		spdifm0_pins: spdifm0-pins {
			rockchip,pins =
				/* spdif_tx_m0 */
				<6 RK_PA0 1 &pcfg_pull_none>;
		};

		/omit-if-no-ref/
		spdifm1_pins: spdifm1-pins {
			rockchip,pins =
				/* spdif_tx_m1 */
				<3 RK_PC2 1 &pcfg_pull_none>;
		};

		/omit-if-no-ref/
		spdifm2_pins: spdifm2-pins {
			rockchip,pins =
				/* spdif_tx_m2 */
				<5 RK_PC2 3 &pcfg_pull_none>;
		};
	};

	spdif_rx_arc {
		/omit-if-no-ref/
		spdif_rx_arc_pins: spdif-rx-arc-pins {
			rockchip,pins =
				/* spdif_rx_arc_testout */
				<5 RK_PA3 4 &pcfg_pull_none>;
		};
	};

	spi0 {
		/omit-if-no-ref/
		spi0m0_pins: spi0m0-pins {
			rockchip,pins =
				/* spi0_clk_m0 */
				<6 RK_PA3 1 &pcfg_pull_none_drv_level_2_75>,
				/* spi0_miso_m0 */
				<6 RK_PC5 1 &pcfg_pull_none_drv_level_2_75>,
				/* spi0_mosi_m0 */
				<6 RK_PC4 1 &pcfg_pull_none_drv_level_2_75>;
		};

		/omit-if-no-ref/
		spi0m0_csn0_pins: spi0m0-csn0-pins {
			rockchip,pins =
				/* spi0m0_csn0 */
				<6 RK_PA2 1 &pcfg_pull_none_drv_level_2_75>;
		};
		/omit-if-no-ref/
		spi0m0_csn1_pins: spi0m0-csn1-pins {
			rockchip,pins =
				/* spi0m0_csn1 */
				<6 RK_PC1 1 &pcfg_pull_none_drv_level_2_75>;
		};

		/omit-if-no-ref/
		spi0m1_pins: spi0m1-pins {
			rockchip,pins =
				/* spi0_clk_m1 */
				<5 RK_PA4 2 &pcfg_pull_none_drv_level_2_75>,
				/* spi0_miso_m1 */
				<5 RK_PA2 2 &pcfg_pull_none_drv_level_2_75>,
				/* spi0_mosi_m1 */
				<5 RK_PA5 2 &pcfg_pull_none_drv_level_2_75>;
		};

		/omit-if-no-ref/
		spi0m1_csn0_pins: spi0m1-csn0-pins {
			rockchip,pins =
				/* spi0m1_csn0 */
				<5 RK_PA3 2 &pcfg_pull_none_drv_level_2_75>;
		};
		/omit-if-no-ref/
		spi0m1_csn1_pins: spi0m1-csn1-pins {
			rockchip,pins =
				/* spi0m1_csn1 */
				<5 RK_PA1 2 &pcfg_pull_none_drv_level_2_75>;
		};
	};

	spi1 {
		/omit-if-no-ref/
		spi1m0_pins: spi1m0-pins {
			rockchip,pins =
				/* spi1_clk_m0 */
				<4 RK_PA1 2 &pcfg_pull_none_drv_level_2_75>,
				/* spi1_miso_m0 */
				<4 RK_PA3 2 &pcfg_pull_none_drv_level_2_75>,
				/* spi1_mosi_m0 */
				<4 RK_PA2 2 &pcfg_pull_none_drv_level_2_75>;
		};

		/omit-if-no-ref/
		spi1m0_csn0_pins: spi1m0-csn0-pins {
			rockchip,pins =
				/* spi1m0_csn0 */
				<4 RK_PA0 2 &pcfg_pull_none_drv_level_2_75>;
		};
		/omit-if-no-ref/
		spi1m0_csn1_pins: spi1m0-csn1-pins {
			rockchip,pins =
				/* spi1m0_csn1 */
				<4 RK_PA4 2 &pcfg_pull_none_drv_level_2_75>;
		};

		/omit-if-no-ref/
		spi1m1_pins: spi1m1-pins {
			rockchip,pins =
				/* spi1_clk_m1 */
				<5 RK_PC3 1 &pcfg_pull_none_drv_level_2_75>,
				/* spi1_miso_m1 */
				<5 RK_PC2 1 &pcfg_pull_none_drv_level_2_75>,
				/* spi1_mosi_m1 */
				<5 RK_PC0 1 &pcfg_pull_none_drv_level_2_75>;
		};

		/omit-if-no-ref/
		spi1m1_csn0_pins: spi1m1-csn0-pins {
			rockchip,pins =
				/* spi1m1_csn0 */
				<5 RK_PA6 2 &pcfg_pull_none_drv_level_2_75>;
		};
		/omit-if-no-ref/
		spi1m1_csn1_pins: spi1m1-csn1-pins {
			rockchip,pins =
				/* spi1m1_csn1 */
				<5 RK_PA7 4 &pcfg_pull_none_drv_level_2_75>;
		};
	};

	tsadc {
		/omit-if-no-ref/
		tsadc_pins: tsadc-pins {
			rockchip,pins =
				/* tsadc_shut */
				<0 RK_PA0 1 &pcfg_pull_none>,
				/* tsadc_shutorg */
				<0 RK_PA0 2 &pcfg_pull_none>;
		};
	};

	uart0 {
		/omit-if-no-ref/
		uart0m0_xfer_pins: uart0m0-xfer-pins {
			rockchip,pins =
				/* uart0_rx_m0 */
				<0 RK_PB7 1 &pcfg_pull_up>,
				/* uart0_tx_m0 */
				<0 RK_PC0 1 &pcfg_pull_up>;
		};

		/omit-if-no-ref/
		uart0m1_xfer_pins: uart0m1-xfer-pins {
			rockchip,pins =
				/* uart0_rx_m1 */
				<2 RK_PA0 2 &pcfg_pull_up>,
				/* uart0_tx_m1 */
				<2 RK_PA1 2 &pcfg_pull_up>;
		};
	};

	uart1 {
		/omit-if-no-ref/
		uart1m0_xfer_pins: uart1m0-xfer-pins {
			rockchip,pins =
				/* uart1_rx_m0 */
				<6 RK_PB6 2 &pcfg_pull_up>,
				/* uart1_tx_m0 */
				<6 RK_PB5 2 &pcfg_pull_up>;
		};

		/omit-if-no-ref/
		uart1m0_ctsn_pins: uart1m0-ctsn-pins {
			rockchip,pins =
				/* uart1m0_ctsn */
				<6 RK_PB3 3 &pcfg_pull_none>;
		};
		/omit-if-no-ref/
		uart1m0_rtsn_pins: uart1m0-rtsn-pins {
			rockchip,pins =
				/* uart1m0_rtsn */
				<6 RK_PB4 3 &pcfg_pull_none>;
		};

		/omit-if-no-ref/
		uart1m1_xfer_pins: uart1m1-xfer-pins {
			rockchip,pins =
				/* uart1_rx_m1 */
				<6 RK_PA3 2 &pcfg_pull_up>,
				/* uart1_tx_m1 */
				<6 RK_PA2 3 &pcfg_pull_up>;
		};

		/omit-if-no-ref/
		uart1m1_ctsn_pins: uart1m1-ctsn-pins {
			rockchip,pins =
				/* uart1m1_ctsn */
				<6 RK_PA0 2 &pcfg_pull_none>;
		};
		/omit-if-no-ref/
		uart1m1_rtsn_pins: uart1m1-rtsn-pins {
			rockchip,pins =
				/* uart1m1_rtsn */
				<6 RK_PA1 3 &pcfg_pull_none>;
		};

		/omit-if-no-ref/
		uart1m2_xfer_pins: uart1m2-xfer-pins {
			rockchip,pins =
				/* uart1_rx_m2 */
				<5 RK_PB4 4 &pcfg_pull_up>,
				/* uart1_tx_m2 */
				<5 RK_PA6 6 &pcfg_pull_up>;
		};

		/omit-if-no-ref/
		uart1m2_ctsn_pins: uart1m2-ctsn-pins {
			rockchip,pins =
				/* uart1m2_ctsn */
				<5 RK_PC2 7 &pcfg_pull_none>;
		};
		/omit-if-no-ref/
		uart1m2_rtsn_pins: uart1m2-rtsn-pins {
			rockchip,pins =
				/* uart1m2_rtsn */
				<5 RK_PC0 7 &pcfg_pull_none>;
		};
	};

	uart2 {
		/omit-if-no-ref/
		uart2m0_xfer_pins: uart2m0-xfer-pins {
			rockchip,pins =
				/* uart2_rx_m0 */
				<3 RK_PA7 1 &pcfg_pull_up>,
				/* uart2_tx_m0 */
				<3 RK_PB0 1 &pcfg_pull_up>;
		};

		/omit-if-no-ref/
		uart2m0_ctsn_pins: uart2m0-ctsn-pins {
			rockchip,pins =
				/* uart2m0_ctsn */
				<3 RK_PB2 1 &pcfg_pull_none>;
		};
		/omit-if-no-ref/
		uart2m0_rtsn_pins: uart2m0-rtsn-pins {
			rockchip,pins =
				/* uart2m0_rtsn */
				<3 RK_PB1 1 &pcfg_pull_none>;
		};

		/omit-if-no-ref/
		uart2m1_xfer_pins: uart2m1-xfer-pins {
			rockchip,pins =
				/* uart2_rx_m1 */
				<5 RK_PA7 3 &pcfg_pull_up>,
				/* uart2_tx_m1 */
				<5 RK_PB0 3 &pcfg_pull_up>;
		};

		/omit-if-no-ref/
		uart2m1_ctsn_pins: uart2m1-ctsn-pins {
			rockchip,pins =
				/* uart2m1_ctsn */
				<5 RK_PB2 3 &pcfg_pull_none>;
		};
		/omit-if-no-ref/
		uart2m1_rtsn_pins: uart2m1-rtsn-pins {
			rockchip,pins =
				/* uart2m1_rtsn */
				<5 RK_PB1 3 &pcfg_pull_none>;
		};
	};

	uart3 {
		/omit-if-no-ref/
		uart3m0_xfer_pins: uart3m0-xfer-pins {
			rockchip,pins =
				/* uart3_rx_m0 */
				<6 RK_PB3 2 &pcfg_pull_up>,
				/* uart3_tx_m0 */
				<6 RK_PB4 2 &pcfg_pull_up>;
		};

		/omit-if-no-ref/
		uart3m1_xfer_pins: uart3m1-xfer-pins {
			rockchip,pins =
				/* uart3_rx_m1 */
				<5 RK_PB6 3 &pcfg_pull_up>,
				/* uart3_tx_m1 */
				<5 RK_PB7 3 &pcfg_pull_up>;
		};

		/omit-if-no-ref/
		uart3m2_xfer_pins: uart3m2-xfer-pins {
			rockchip,pins =
				/* uart3_rx_m2 */
				<0 RK_PD1 1 &pcfg_pull_up>,
				/* uart3_tx_m2 */
				<0 RK_PD0 1 &pcfg_pull_up>;
		};

		/omit-if-no-ref/
		uart3_ctsn_pins: uart3-ctsn-pins {
			rockchip,pins =
				/* uart3_ctsn */
				<0 RK_PD2 2 &pcfg_pull_none>;
		};
		/omit-if-no-ref/
		uart3_rtsn_pins: uart3-rtsn-pins {
			rockchip,pins =
				/* uart3_rtsn */
				<0 RK_PD3 2 &pcfg_pull_none>;
		};
	};

	uart4 {
		/omit-if-no-ref/
		uart4m0_xfer_pins: uart4m0-xfer-pins {
			rockchip,pins =
				/* uart4_rx_m0 */
				<2 RK_PA0 3 &pcfg_pull_up>,
				/* uart4_tx_m0 */
				<2 RK_PA1 3 &pcfg_pull_up>;
		};

		/omit-if-no-ref/
		uart4m0_ctsn_pins: uart4m0-ctsn-pins {
			rockchip,pins =
				/* uart4m0_ctsn */
				<2 RK_PA3 3 &pcfg_pull_none>;
		};
		/omit-if-no-ref/
		uart4m0_rtsn_pins: uart4m0-rtsn-pins {
			rockchip,pins =
				/* uart4m0_rtsn */
				<2 RK_PA2 3 &pcfg_pull_none>;
		};

		/omit-if-no-ref/
		uart4m1_xfer_pins: uart4m1-xfer-pins {
			rockchip,pins =
				/* uart4_rx_m1 */
				<1 RK_PA2 3 &pcfg_pull_up>,
				/* uart4_tx_m1 */
				<1 RK_PA3 3 &pcfg_pull_up>;
		};

		/omit-if-no-ref/
		uart4m1_ctsn_pins: uart4m1-ctsn-pins {
			rockchip,pins =
				/* uart4m1_ctsn */
				<1 RK_PA1 3 &pcfg_pull_none>;
		};
		/omit-if-no-ref/
		uart4m1_rtsn_pins: uart4m1-rtsn-pins {
			rockchip,pins =
				/* uart4m1_rtsn */
				<1 RK_PA0 3 &pcfg_pull_none>;
		};
	};

	uart5 {
		/omit-if-no-ref/
		uart5m0_xfer_pins: uart5m0-xfer-pins {
			rockchip,pins =
				/* uart5_rx_m0 */
				<5 RK_PA1 4 &pcfg_pull_up>,
				/* uart5_tx_m0 */
				<5 RK_PA0 3 &pcfg_pull_up>;
		};

		/omit-if-no-ref/
		uart5m1_xfer_pins: uart5m1-xfer-pins {
			rockchip,pins =
				/* uart5_rx_m1 */
				<5 RK_PC2 4 &pcfg_pull_up>,
				/* uart5_tx_m1 */
				<5 RK_PC0 4 &pcfg_pull_up>;
		};

		/omit-if-no-ref/
		uart5_ctsn_pins: uart5-ctsn-pins {
			rockchip,pins =
				/* uart5_ctsn */
				<5 RK_PA6 5 &pcfg_pull_none>;
		};
		/omit-if-no-ref/
		uart5_rtsn_pins: uart5-rtsn-pins {
			rockchip,pins =
				/* uart5_rtsn */
				<5 RK_PC3 5 &pcfg_pull_none>;
		};
	};

	vop_vsync {
		/omit-if-no-ref/
		vop_vsync_pins: vop-vsync-pins {
			rockchip,pins =
				/* vop_vsync_testout */
				<2 RK_PA6 2 &pcfg_pull_none>;
		};
	};
};

/*
 * This part is edited handly.
 */
&pinctrl {
	pdm {
		/omit-if-no-ref/
		pdmm0_clk0_idle: pdmm0-clk0-idle {
			rockchip,pins =
				/* pdm_clk0_m0 */
				<6 RK_PA5 RK_FUNC_GPIO &pcfg_pull_none>;
		};

		/omit-if-no-ref/
		pdmm0_clk1_idle: pdmm0-clk1-idle {
			rockchip,pins =
				/* pdm_clk1_m0 */
				<6 RK_PA7 RK_FUNC_GPIO &pcfg_pull_none>;
		};

		/omit-if-no-ref/
		pdmm1_clk0_idle: pdmm1-clk0-idle {
			rockchip,pins =
				/* pdm_clk0_m1 */
				<5 RK_PA6 RK_FUNC_GPIO &pcfg_pull_none>;
		};

		/omit-if-no-ref/
		pdmm1_clk1_idle: pdmm1-clk1-idle {
			rockchip,pins =
				/* pdm_clk1_m1 */
				<5 RK_PB7 RK_FUNC_GPIO &pcfg_pull_none>;
		};
	};
};
